AUTOSAR XML (schema 314)
package /ComponentType
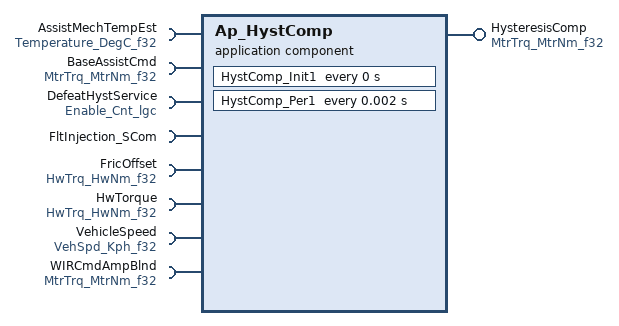
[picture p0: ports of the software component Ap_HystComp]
  application software component type Ap_HystComp
    provide port HysteresisComp: unqueued-sender-com-spec{data-element=MtrNm_f32, can-invalidate=false, init-value=D_ZERO_ULS_F32}, provided-interface=MtrTrq_MtrNm_f32
    8 x require port:
      AssistMechTempEst: unqueued-receiver-com-spec{data-element=DegC_f32, init-value=D_ZERO_ULS_F32}, required-interface=Temperature_DegC_f32
      BaseAssistCmd: unqueued-receiver-com-spec{data-element=MtrNm_f32, init-value=D_ZERO_ULS_F32}, required-interface=MtrTrq_MtrNm_f32
      DefeatHystService: unqueued-receiver-com-spec{data-element=Cnt_lgc, init-value=D_FALSE_CNT_LGC}, required-interface=Enable_Cnt_lgc
      FltInjection_SCom: client-com-spec=FltInjection, required-interface=FltInjection_SCom
      FricOffset: unqueued-receiver-com-spec{data-element=HwNm_f32, init-value=D_ZERO_ULS_F32}, required-interface=HwTrq_HwNm_f32
      HwTorque: unqueued-receiver-com-spec{data-element=HwNm_f32, init-value=D_ZERO_ULS_F32}, required-interface=HwTrq_HwNm_f32
      VehicleSpeed: unqueued-receiver-com-spec{data-element=Kph_f32, init-value=D_ZERO_ULS_F32}, required-interface=VehSpd_Kph_f32
      WIRCmdAmpBlnd: unqueued-receiver-com-spec{data-element=MtrNm_f32, init-value=D_ZERO_ULS_F32}, required-interface=MtrTrq_MtrNm_f32
  internal behavior Ap_HystComp_InternalBehavior: component=Ap_HystComp
    timing event HystComp_Init1_InitEvent: start-on-event=HystComp_Init1, period=0
    timing event TMT_HystComp_Per1: start-on-event=HystComp_Per1, period=0.002
    port-api-options:
      enable-take-address=false, indirect-api=false, port=AssistMechTempEst
      enable-take-address=false, indirect-api=false, port=BaseAssistCmd
      enable-take-address=false, indirect-api=false, port=DefeatHystService
      enable-take-address=false, indirect-api=false, port=FltInjection_SCom
      enable-take-address=false, indirect-api=false, port=FricOffset
      enable-take-address=false, indirect-api=false, port=HwTorque
      enable-take-address=false, indirect-api=false, port=HysteresisComp
      enable-take-address=false, indirect-api=false, port=VehicleSpeed
      enable-take-address=false, indirect-api=false, port=WIRCmdAmpBlnd
    runnable HystComp_Init1
    runnable HystComp_Per1
      7 x data read access:
        READ_AssistMechTempEst_DegC_f32: data-element=AssistMechTempEst.DegC_f32
        READ_BaseAssistCmd_MtrNm_f32: data-element=BaseAssistCmd.MtrNm_f32
        READ_DefeatHystService_Cnt_lgc: data-element=DefeatHystService.Cnt_lgc
        READ_FricOffset_HwNm_f32: data-element=FricOffset.HwNm_f32
        READ_HwTorque_HwNm_f32: data-element=HwTorque.HwNm_f32
        READ_VehicleSpeed_Kph_f32: data-element=VehicleSpeed.Kph_f32
        READ_WIRCmdAmpBlnd_MtrNm_f32: data-element=WIRCmdAmpBlnd.MtrNm_f32
      data write access WRITE_HysteresisComp_MtrNm_f32: data-element=HysteresisComp.MtrNm_f32
      sync call SC_FltInjection_SCom_FltInjection: operation=FltInjection_SCom.FltInjection, timeout=0
  swc implementation Ap_HystComp_Implementation: behavior=Ap_HystComp_InternalBehavior
    code-descriptors:
      code Code: type=SRC
